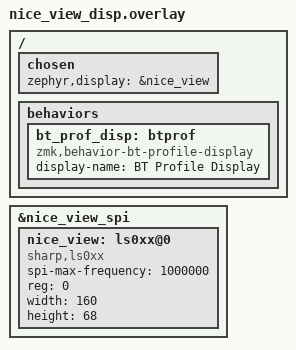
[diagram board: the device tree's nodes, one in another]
/*
 * Copyright (c) 2022 The ZMK Contributors
 *
 * SPDX-License-Identifier: MIT
 */

&nice_view_spi {
    status = "okay";
    nice_view: ls0xx@0 {
        compatible = "sharp,ls0xx";
        spi-max-frequency = <1000000>;
        reg = <0>;
        width = <160>;
        height = <68>;
    };
};

/ {
    chosen {
        zephyr,display = &nice_view;
    };
};

/ {
    behaviors {
        // The left half uses this to tell the right half which Bluetooth
        // profile is active. It is sent over the split link by name, so the
        // node name must be 8 characters or less.
        bt_prof_disp: btprof {
            compatible = "zmk,behavior-bt-profile-display";
            #binding-cells = <1>;
            display-name = "BT Profile Display";
        };
    };
};
